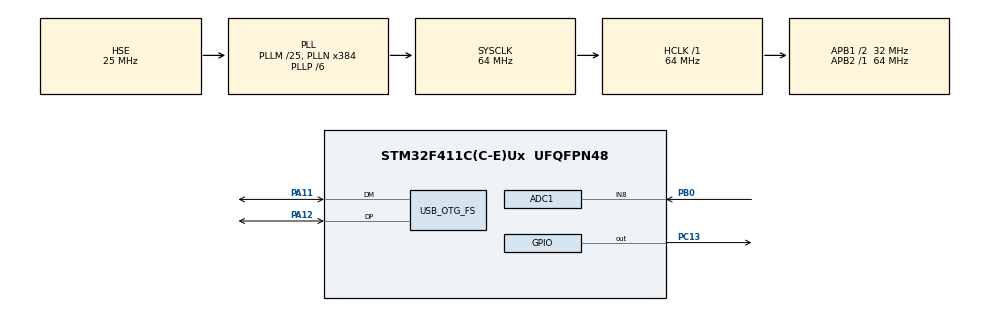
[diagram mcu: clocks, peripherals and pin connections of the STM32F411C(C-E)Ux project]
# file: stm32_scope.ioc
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ADC1.Channel-0\#ChannelRegularConversion=ADC_CHANNEL_8
ADC1.ContinuousConvMode=DISABLE
ADC1.DMAContinuousRequests=ENABLE
ADC1.ExternalTrigConv=ADC_EXTERNALTRIGCONV_T2_TRGO
ADC1.InjNumberOfConversion=0
ADC1.NbrOfConversionFlag=1
ADC1.Rank-0\#ChannelRegularConversion=1
ADC1.Resolution=ADC_RESOLUTION_12B
ADC1.SamplingTime-0\#ChannelRegularConversion=ADC_SAMPLETIME_3CYCLES
ADC1.master=1
Dma.ADC1.0.Direction=DMA_PERIPH_TO_MEMORY
Dma.ADC1.0.FIFOMode=DMA_FIFOMODE_DISABLE
Dma.ADC1.0.Instance=DMA2_Stream0
Dma.ADC1.0.MemDataAlignment=DMA_MDATAALIGN_HALFWORD
Dma.ADC1.0.MemInc=DMA_MINC_ENABLE
Dma.ADC1.0.Mode=DMA_CIRCULAR
Dma.ADC1.0.PeriphDataAlignment=DMA_PDATAALIGN_HALFWORD
Dma.ADC1.0.PeriphInc=DMA_PINC_DISABLE
Dma.ADC1.0.Priority=DMA_PRIORITY_LOW
Dma.Request0=ADC1
FREERTOS.Tasks01=defaultTask,24,128,StartDefaultTask,Default,NULL,Dynamic,NULL,NULL
FREERTOS.configUSE_NEWLIB_REENTRANT=1
Mcu.Family=STM32F4
Mcu.Name=STM32F411C(C-E)Ux
Mcu.Package=UFQFPN48
NVIC.DMA2_Stream0_IRQn=true\:5\:0\:false\:false\:true\:true\:false\:true\:true
NVIC.OTG_FS_IRQn=true\:5\:0\:false\:false\:true\:true\:false\:true\:true
NVIC.PriorityGroup=NVIC_PRIORITYGROUP_4
NVIC.TIM3_IRQn=true\:15\:0\:false\:false\:true\:false\:false\:true\:true
NVIC.TimeBase=TIM3_IRQn
NVIC.TimeBaseIP=TIM3
PA11.Mode=Device_Only
PA11.Signal=USB_OTG_FS_DM
PA12.Mode=Device_Only
PA12.Signal=USB_OTG_FS_DP
PB0.Signal=ADCx_IN8
PC13-ANTI_TAMP.Signal=GPIO_Output
PH0\ -\ OSC_IN.Mode=HSE-External-Oscillator
PH0\ -\ OSC_IN.Signal=RCC_OSC_IN
PH1\ -\ OSC_OUT.Mode=HSE-External-Oscillator
PH1\ -\ OSC_OUT.Signal=RCC_OSC_OUT
ProjectManager.HeapSize=0x200
ProjectManager.StackSize=0x400
ProjectManager.TargetToolchain=STM32CubeIDE
RCC.48MHZClocksFreq_Value=48000000
RCC.AHBFreq_Value=64000000
RCC.APB1CLKDivider=RCC_HCLK_DIV2
RCC.APB1Freq_Value=32000000
RCC.APB1TimFreq_Value=64000000
RCC.APB2Freq_Value=64000000
RCC.APB2TimFreq_Value=64000000
RCC.CortexFreq_Value=64000000
RCC.EnbaleCSS=true
RCC.HCLKFreq_Value=64000000
RCC.HSE_VALUE=25000000
RCC.HSI_VALUE=16000000
RCC.LSE_VALUE=32768
RCC.PLLM=25
RCC.PLLN=384
RCC.PLLP=RCC_PLLP_DIV6
RCC.PLLQ=8
RCC.SYSCLKFreq_VALUE=64000000
RCC.SYSCLKSource=RCC_SYSCLKSOURCE_PLLCLK
RCC.VCOOutputFreq_Value=384000000
SH.ADCx_IN8.0=ADC1_IN8,IN8
TIM2.Period=32 - 1
TIM2.Prescaler=0
TIM2.TIM_MasterOutputTrigger=TIM_TRGO_UPDATE
TIM2.TIM_MasterSlaveMode=TIM_MASTERSLAVEMODE_DISABLE
TIM5.Prescaler=64 - 1
USB_DEVICE.CLASS_NAME_FS=CDC
USB_DEVICE.VirtualMode=Cdc
USB_DEVICE.VirtualModeFS=Cdc_FS
USB_OTG_FS.VirtualMode=Device_Only
VP_FREERTOS_VS_CMSIS_V2.Mode=CMSIS_V2
VP_SYS_VS_tim3.Mode=TIM3
VP_TIM2_VS_ClockSourceINT.Mode=Internal
VP_TIM5_VS_ClockSourceINT.Mode=Internal
VP_USB_DEVICE_VS_USB_DEVICE_CDC_FS.Mode=CDC_FS
board=custom

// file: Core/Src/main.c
/* USER CODE BEGIN Header */
/**
  ******************************************************************************
  * @file           : main.c
  * @brief          : Main program body
  ******************************************************************************
  * @attention
  *
  * Copyright (c) 2026 STMicroelectronics.
  * All rights reserved.
  *
  * This software is licensed under terms that can be found in the LICENSE file
  * in the root directory of this software component.
  * If no LICENSE file comes with this software, it is provided AS-IS.
  *
  ******************************************************************************
  */
/* USER CODE END Header */
#include "main.h"
#include "cmsis_os.h"
#include "adc.h"
#include "dma.h"
#include "tim.h"
#include "usb_device.h"
#include "gpio.h"

void SystemClock_Config(void);
void MX_FREERTOS_Init(void);

int main(void)
{

  /* MCU Configuration--------------------------------------------------------*/

  /* Reset of all peripherals, Initializes the Flash interface and the Systick. */
  HAL_Init();

  /* Configure the system clock */
  SystemClock_Config();

  /* Initialize all configured peripherals */
  MX_GPIO_Init();
  MX_DMA_Init();
  MX_ADC1_Init();
  MX_TIM2_Init();
  MX_TIM5_Init();

  /* Init scheduler */
  osKernelInitialize();  /* Call init function for freertos objects (in cmsis_os2.c) */
  MX_FREERTOS_Init();

  /* Start scheduler */
  osKernelStart();

  /* We should never get here as control is now taken by the scheduler */

  /* Infinite loop */
  while (1)
  {

  }
}

void SystemClock_Config(void)
{
  RCC_OscInitTypeDef RCC_OscInitStruct = {0};
  RCC_ClkInitTypeDef RCC_ClkInitStruct = {0};

  /** Configure the main internal regulator output voltage
  */
  __HAL_RCC_PWR_CLK_ENABLE();
  __HAL_PWR_VOLTAGESCALING_CONFIG(PWR_REGULATOR_VOLTAGE_SCALE1);

  /** Initializes the RCC Oscillators according to the specified parameters
  * in the RCC_OscInitTypeDef structure.
  */
  RCC_OscInitStruct.OscillatorType = RCC_OSCILLATORTYPE_HSE;
  RCC_OscInitStruct.HSEState = RCC_HSE_ON;
  RCC_OscInitStruct.PLL.PLLState = RCC_PLL_ON;
  RCC_OscInitStruct.PLL.PLLSource = RCC_PLLSOURCE_HSE;
  RCC_OscInitStruct.PLL.PLLM = 25;
  RCC_OscInitStruct.PLL.PLLN = 384;
  RCC_OscInitStruct.PLL.PLLP = RCC_PLLP_DIV6;
  RCC_OscInitStruct.PLL.PLLQ = 8;
  if (HAL_RCC_OscConfig(&RCC_OscInitStruct) != HAL_OK)
  {
    Error_Handler();
  }

  /** Initializes the CPU, AHB and APB buses clocks
  */
  RCC_ClkInitStruct.ClockType = RCC_CLOCKTYPE_HCLK|RCC_CLOCKTYPE_SYSCLK
                              |RCC_CLOCKTYPE_PCLK1|RCC_CLOCKTYPE_PCLK2;
  RCC_ClkInitStruct.SYSCLKSource = RCC_SYSCLKSOURCE_PLLCLK;
  RCC_ClkInitStruct.AHBCLKDivider = RCC_SYSCLK_DIV1;
  RCC_ClkInitStruct.APB1CLKDivider = RCC_HCLK_DIV2;
  RCC_ClkInitStruct.APB2CLKDivider = RCC_HCLK_DIV1;

  if (HAL_RCC_ClockConfig(&RCC_ClkInitStruct, FLASH_LATENCY_1) != HAL_OK)
  {
    Error_Handler();
  }

  /** Enables the Clock Security System
  */
  HAL_RCC_EnableCSS();
}

void HAL_TIM_PeriodElapsedCallback(TIM_HandleTypeDef *htim)
{
  if (htim->Instance == TIM3)
  {
    HAL_IncTick();
  }
}

void Error_Handler(void)
{
  __disable_irq();
  while (1)
  {
  }
}

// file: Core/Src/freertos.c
/* USER CODE BEGIN Header */
/**
  ******************************************************************************
  * File Name          : freertos.c
  * Description        : Code for freertos applications
  ******************************************************************************
  * @attention
  *
  * Copyright (c) 2026 STMicroelectronics.
  * All rights reserved.
  *
  * This software is licensed under terms that can be found in the LICENSE file
  * in the root directory of this software component.
  * If no LICENSE file comes with this software, it is provided AS-IS.
  *
  ******************************************************************************
  */
/* USER CODE END Header */

#include "FreeRTOS.h"
#include "task.h"
#include "main.h"
#include "cmsis_os.h"

/* USER CODE BEGIN Includes */

#include "oscilloscope_tasks.h"

/* USER CODE END Includes */

/* Definitions for defaultTask */
osThreadId_t defaultTaskHandle;
const osThreadAttr_t defaultTask_attributes = {
  .name = "defaultTask",
  .stack_size = 128 * 4,
  .priority = (osPriority_t) osPriorityNormal,
};

void StartDefaultTask(void *argument);

extern void MX_USB_DEVICE_Init(void);
void MX_FREERTOS_Init(void); /* (MISRA C 2004 rule 8.1) */

void MX_FREERTOS_Init(void) {

  /* Create the thread(s) */
  /* creation of defaultTask */
  defaultTaskHandle = osThreadNew(StartDefaultTask, NULL, &defaultTask_attributes);

  /* USER CODE BEGIN RTOS_THREADS */
  main_task_init();
  usb_in_task_init();
  /* USER CODE END RTOS_THREADS */

}

void StartDefaultTask(void *argument)
{
  /* init code for USB_DEVICE */
  MX_USB_DEVICE_Init();
  for(;;)
  {
    osDelay(1);
  }
}
